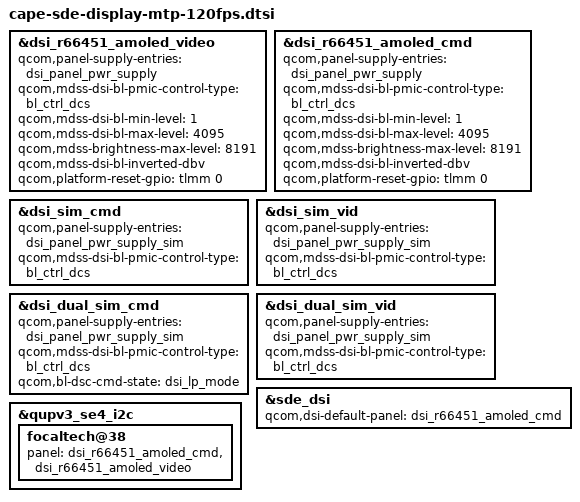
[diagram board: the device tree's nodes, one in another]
#include "cape-sde-display.dtsi"

&dsi_r66451_amoled_video {
	qcom,panel-supply-entries = <&dsi_panel_pwr_supply>;
	qcom,mdss-dsi-bl-pmic-control-type = "bl_ctrl_dcs";
	qcom,mdss-dsi-bl-min-level = <1>;
	qcom,mdss-dsi-bl-max-level = <4095>;
	qcom,mdss-brightness-max-level = <8191>;
	qcom,mdss-dsi-bl-inverted-dbv;
	qcom,platform-reset-gpio = <&tlmm 0 0>;
};

&dsi_r66451_amoled_cmd {
	qcom,panel-supply-entries = <&dsi_panel_pwr_supply>;
	qcom,mdss-dsi-bl-pmic-control-type = "bl_ctrl_dcs";
	qcom,mdss-dsi-bl-min-level = <1>;
	qcom,mdss-dsi-bl-max-level = <4095>;
	qcom,mdss-brightness-max-level = <8191>;
	qcom,mdss-dsi-bl-inverted-dbv;
	qcom,platform-reset-gpio = <&tlmm 0 0>;
};

&dsi_sim_cmd {
	qcom,panel-supply-entries = <&dsi_panel_pwr_supply_sim>;
	qcom,mdss-dsi-bl-pmic-control-type = "bl_ctrl_dcs";
};

&dsi_sim_vid {
	qcom,panel-supply-entries = <&dsi_panel_pwr_supply_sim>;
	qcom,mdss-dsi-bl-pmic-control-type = "bl_ctrl_dcs";
};

&dsi_dual_sim_cmd {
	qcom,panel-supply-entries = <&dsi_panel_pwr_supply_sim>;
	qcom,mdss-dsi-bl-pmic-control-type = "bl_ctrl_dcs";
	qcom,bl-dsc-cmd-state = "dsi_lp_mode";
};

&dsi_dual_sim_vid {
	qcom,panel-supply-entries = <&dsi_panel_pwr_supply_sim>;
	qcom,mdss-dsi-bl-pmic-control-type = "bl_ctrl_dcs";
};

&sde_dsi {
	qcom,dsi-default-panel = <&dsi_r66451_amoled_cmd>;
};

&qupv3_se4_i2c {
	focaltech@38 {
		panel = <&dsi_r66451_amoled_cmd
			&dsi_r66451_amoled_video>;
	};
};
